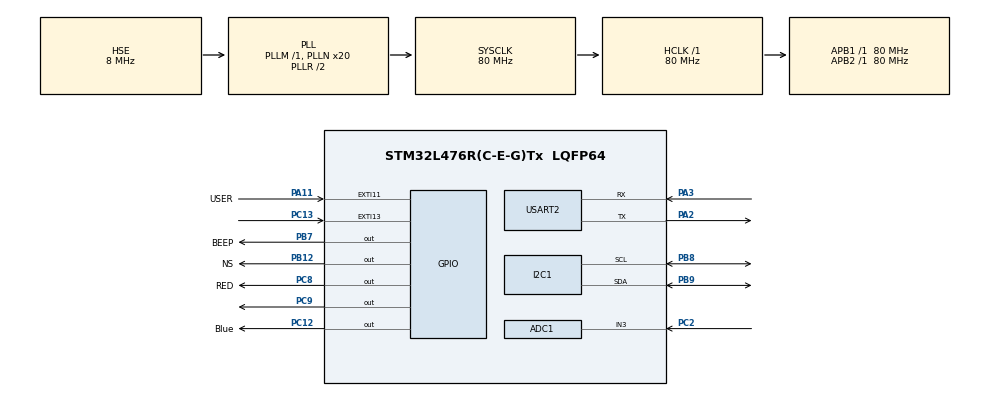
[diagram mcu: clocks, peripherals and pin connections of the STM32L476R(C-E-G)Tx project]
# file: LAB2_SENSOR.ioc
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ADC1.Channel-3\#ChannelRegularConversion=ADC_CHANNEL_3
ADC1.NbrOfConversion=1
ADC1.NbrOfConversionFlag=1
ADC1.OffsetNumber-3\#ChannelRegularConversion=ADC_OFFSET_NONE
ADC1.Rank-3\#ChannelRegularConversion=1
ADC1.SamplingTime-3\#ChannelRegularConversion=ADC_SAMPLETIME_2CYCLES_5
ADC1.master=1
I2C1.Timing=0x10909CEC
Mcu.Family=STM32L4
Mcu.Name=STM32L476R(C-E-G)Tx
Mcu.Package=LQFP64
NVIC.EXTI15_10_IRQn=true\:4\:0\:true\:false\:true\:true\:true\:true
NVIC.PriorityGroup=NVIC_PRIORITYGROUP_4
NVIC.TIM2_IRQn=true\:0\:0\:false\:false\:true\:true\:true\:true
PA11.GPIO_Label=USER
PA11.Signal=GPXTI11
PA13\ (JTMS-SWDIO).Mode=Serial_Wire
PA13\ (JTMS-SWDIO).Signal=SYS_JTMS-SWDIO
PA14\ (JTCK-SWCLK).Mode=Serial_Wire
PA14\ (JTCK-SWCLK).Signal=SYS_JTCK-SWCLK
PA2.Mode=Asynchronous
PA2.Signal=USART2_TX
PA3.Mode=Asynchronous
PA3.Signal=USART2_RX
PB12.GPIO_Label=NS
PB12.Signal=GPIO_Output
PB7.GPIO_Label=BEEP
PB7.GPIO_Speed=GPIO_SPEED_FREQ_VERY_HIGH
PB7.Signal=GPIO_Output
PB8.Mode=I2C
PB8.Signal=I2C1_SCL
PB9.Mode=I2C
PB9.Signal=I2C1_SDA
PC12.GPIO_Label=Blue
PC12.GPIO_Speed=GPIO_SPEED_FREQ_HIGH
PC12.PinState=GPIO_PIN_SET
PC12.Signal=GPIO_Output
PC13.Signal=GPXTI13
PC2.Signal=ADCx_IN3
PC8.GPIO_Label=RED
PC8.GPIO_Speed=GPIO_SPEED_FREQ_HIGH
PC8.PinState=GPIO_PIN_SET
PC8.Signal=GPIO_Output
PC9.Signal=GPIO_Output
PH0-OSC_IN\ (PH0).Mode=HSE-External-Oscillator
PH0-OSC_IN\ (PH0).Signal=RCC_OSC_IN
PH1-OSC_OUT\ (PH1).Mode=HSE-External-Oscillator
PH1-OSC_OUT\ (PH1).Signal=RCC_OSC_OUT
ProjectManager.HeapSize=0x200
ProjectManager.StackSize=0x400
ProjectManager.TargetToolchain=STM32CubeIDE
RCC.ADCFreq_Value=32000000
RCC.AHBFreq_Value=80000000
RCC.APB1Freq_Value=80000000
RCC.APB1TimFreq_Value=80000000
RCC.APB2Freq_Value=80000000
RCC.APB2TimFreq_Value=80000000
RCC.CortexFreq_Value=80000000
RCC.HCLKFreq_Value=80000000
RCC.HSE_VALUE=8000000
RCC.HSI_VALUE=16000000
RCC.LSE_VALUE=32768
RCC.MSI_VALUE=4000000
RCC.PLLN=20
RCC.PLLSourceVirtual=RCC_PLLSOURCE_HSE
RCC.SYSCLKFreq_VALUE=80000000
RCC.SYSCLKSource=RCC_SYSCLKSOURCE_PLLCLK
RCC.USBFreq_Value=32000000
RCC.VCOOutputFreq_Value=160000000
SH.ADCx_IN3.0=ADC1_IN3,IN3-Single-Ended
TIM2.CounterMode=TIM_COUNTERMODE_DOWN
TIM2.Period=2
TIM2.Prescaler=79
USART2.VirtualMode-Asynchronous=VM_ASYNC
VP_TIM2_VS_ClockSourceINT.Mode=Internal
board=custom

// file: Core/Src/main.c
/* USER CODE BEGIN Header */
/**
  ******************************************************************************
  * @file           : main.c
  * @brief          : Main program body
  ******************************************************************************
  * @attention
  *
  * Copyright (c) 2023 STMicroelectronics.
  * All rights reserved.
  *
  * This software is licensed under terms that can be found in the LICENSE file
  * in the root directory of this software component.
  * If no LICENSE file comes with this software, it is provided AS-IS.
  *
  ******************************************************************************
  */
/* USER CODE END Header */
#include "main.h"
#include "adc.h"
#include "i2c.h"
#include "tim.h"
#include "usart.h"
#include "gpio.h"

/* USER CODE BEGIN Includes */
#include "printf.h"
#include "mydelay.h"
#include "Flame.h"
#include "music.h"
/* USER CODE END Includes */

void SystemClock_Config(void);

int main(void)
{

  /* MCU Configuration--------------------------------------------------------*/

  /* Reset of all peripherals, Initializes the Flash interface and the Systick. */
  HAL_Init();

  /* USER CODE BEGIN Init */
  bool Fire_Situatio=FALSE;
  /* USER CODE END Init */

  /* Configure the system clock */
  SystemClock_Config();

  /* Initialize all configured peripherals */
  MX_GPIO_Init();
  MX_TIM2_Init();
  MX_USART2_UART_Init();
  MX_ADC1_Init();
  MX_I2C1_Init();
  /* USER CODE BEGIN 2 */
  //LSM6DSOInit();

  /* USER CODE END 2 */

  /* Infinite loop */
  /* USER CODE BEGIN WHILE */
  while (1)
  {
	  Fire_Situatio=Fire();
	  HAL_Delay(500);

	 // LSM6DSOPolling();
    /* USER CODE END WHILE */

  }
}

void SystemClock_Config(void)
{
  RCC_OscInitTypeDef RCC_OscInitStruct = {0};
  RCC_ClkInitTypeDef RCC_ClkInitStruct = {0};

  /** Configure the main internal regulator output voltage
  */
  if (HAL_PWREx_ControlVoltageScaling(PWR_REGULATOR_VOLTAGE_SCALE1) != HAL_OK)
  {
    Error_Handler();
  }

  /** Initializes the RCC Oscillators according to the specified parameters
  * in the RCC_OscInitTypeDef structure.
  */
  RCC_OscInitStruct.OscillatorType = RCC_OSCILLATORTYPE_HSE;
  RCC_OscInitStruct.HSEState = RCC_HSE_ON;
  RCC_OscInitStruct.PLL.PLLState = RCC_PLL_ON;
  RCC_OscInitStruct.PLL.PLLSource = RCC_PLLSOURCE_HSE;
  RCC_OscInitStruct.PLL.PLLM = 1;
  RCC_OscInitStruct.PLL.PLLN = 20;
  RCC_OscInitStruct.PLL.PLLP = RCC_PLLP_DIV7;
  RCC_OscInitStruct.PLL.PLLQ = RCC_PLLQ_DIV2;
  RCC_OscInitStruct.PLL.PLLR = RCC_PLLR_DIV2;
  if (HAL_RCC_OscConfig(&RCC_OscInitStruct) != HAL_OK)
  {
    Error_Handler();
  }

  /** Initializes the CPU, AHB and APB buses clocks
  */
  RCC_ClkInitStruct.ClockType = RCC_CLOCKTYPE_HCLK|RCC_CLOCKTYPE_SYSCLK
                              |RCC_CLOCKTYPE_PCLK1|RCC_CLOCKTYPE_PCLK2;
  RCC_ClkInitStruct.SYSCLKSource = RCC_SYSCLKSOURCE_PLLCLK;
  RCC_ClkInitStruct.AHBCLKDivider = RCC_SYSCLK_DIV1;
  RCC_ClkInitStruct.APB1CLKDivider = RCC_HCLK_DIV1;
  RCC_ClkInitStruct.APB2CLKDivider = RCC_HCLK_DIV1;

  if (HAL_RCC_ClockConfig(&RCC_ClkInitStruct, FLASH_LATENCY_4) != HAL_OK)
  {
    Error_Handler();
  }
}

/* USER CODE BEGIN 4 */
void HAL_GPIO_EXTI_Callback(uint16_t GPIO_Pin)
{
  if (GPIO_Pin == GPIO_PIN_13) {
    HAL_GPIO_TogglePin(RED_GPIO_Port,RED_Pin); /* blink LED */
    HAL_GPIO_TogglePin(BEEP_GPIO_Port, BEEP_Pin);
  }
}
/* USER CODE END 4 */

void Error_Handler(void)
{
  __disable_irq();
  while (1)
  {
  }
}
